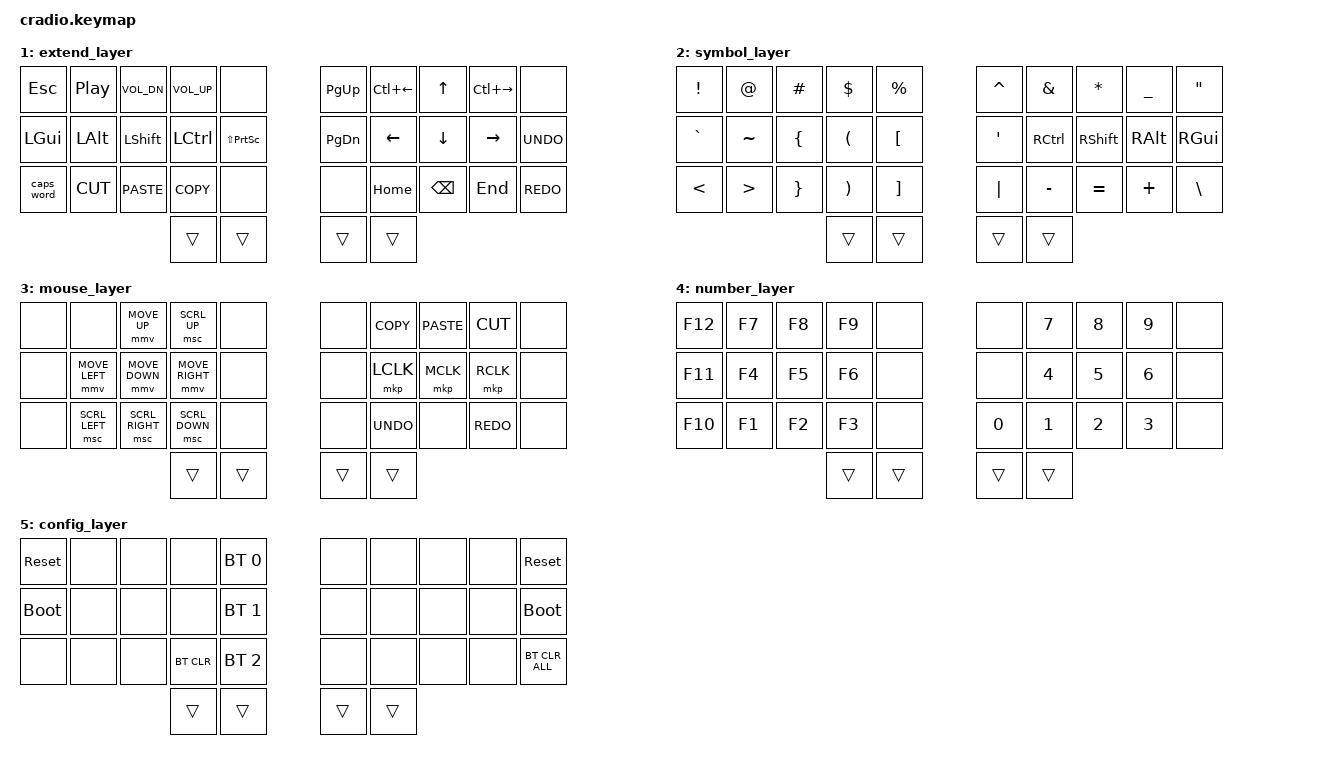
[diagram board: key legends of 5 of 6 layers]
// Copyright (c) 2022 The ZMK Contributors
// SPDX-License-Identifier: MIT

#include <behaviors.dtsi>
#include <dt-bindings/zmk/keys.h>
#include <dt-bindings/zmk/bt.h>
#include <dt-bindings/zmk/mouse.h>

// Home row mods macro
#define HRML(k1,k2,k3,k4) &ht_l LGUI k1  &ht_l LALT k2  &ht LSHFT k3  &ht LCTRL k4
#define HRMR(k1,k2,k3,k4) &ht RCTRL k1  &ht RSHFT k2  &ht_l RALT k3  &ht_l RGUI k4

// Word Nav
#define NXTWD &kp LC(RIGHT)
#define PRVWD &kp LC(LEFT)

// Media
#define VOL_DN &kp C_VOL_DN
#define VOL_UP &kp C_VOL_UP

// Mouse
#define MV_UP &mmv MOVE_UP
#define MV_DOWN &mmv MOVE_DOWN
#define MV_LEFT &mmv MOVE_LEFT
#define MV_RIGHT &mmv MOVE_RIGHT

// Scroll
#define SC_UP &msc SCRL_UP
#define SC_DOWN &msc SCRL_DOWN
#define SC_LEFT &msc SCRL_LEFT
#define SC_RIGHT &msc SCRL_RIGHT

// Screenshot
#define SCN_SHOT &kp LS(PSCRN)

/ {
    behaviors {
        ht: hold_tap {
            compatible = "zmk,behavior-hold-tap";
            #binding-cells = <2>;
            flavor = "tap-preferred";
            tapping-term-ms = <220>;
    		quick-tap-ms = <200>;
    		require-prior-idle-ms = <125>;
            bindings = <&kp>, <&kp>;
        };
        ht_l: hold_tap_long {
            compatible = "zmk,behavior-hold-tap";
            #binding-cells = <2>;
            flavor = "tap-preferred";
            tapping-term-ms = <400>;
    		quick-tap-ms = <200>;
    		require-prior-idle-ms = <125>;
            bindings = <&kp>, <&kp>;
        };
    };

    conditional_layers {
        compatible = "zmk,conditional-layers";
        config_layer {
            if-layers = <1 2>;
            then-layer = <5>;
        };
    };

    keymap {
        compatible = "zmk,keymap";
        default_layer {
            bindings = <
        //╭──────────┬──────────┬──────────┬──────────┬──────────╮   ╭──────────┬──────────┬──────────┬──────────┬──────────╮
        //│  Q       │  W       │  F       │  P       │  B       │   │  J       │  L       │  U       │  Y       │  ; :     │
            &kp Q      &kp W      &kp F      &kp P      &kp B          &kp J      &kp L      &kp U      &kp Y      &kp SEMI
        //├──────────┼──────────┼──────────┼──────────┼──────────┤   ├──────────┼──────────┼──────────┼──────────┼──────────┤
        //│  A       │  R       │  S       │  T       │  G       │   │  M       │  N       │  E       │  I       │  O       │
            HRML(A,    R,         S,         T)         &kp G          &kp M      HRMR(N,    E,         I,         O)
        //├──────────┼──────────┼──────────┼──────────┼──────────┤   ├──────────┼──────────┼──────────┼──────────┼──────────┤
        //│  Z       │  X       │  C       │  D       │  V       │   │  K       │  H       │  , <     │  . >     │  / ?     │
            &kp Z      &kp X      &kp C      &kp D      &kp V          &kp K      &kp H      &kp COMMA  &kp DOT    &kp FSLH
        //╰──────────┴──────────┴──────────┼──────────┼──────────┤   ├──────────┼──────────┼──────────┴──────────┴──────────╯
                                            &lt 2 TAB  &lt 4 SPACE    &lt 3 ENTER &lt 1 BSPC
        //                                 ╰──────────┴──────────╯   ╰──────────┴──────────╯
            >;
        };

        extend_layer {
            bindings = <
        //╭──────────┬──────────┬──────────┬──────────┬──────────╮   ╭──────────┬──────────┬──────────┬──────────┬──────────╮
        //│  ESC     │Play/Pause│  VOL_DN  │  VOL_UP  │          │   │  PG_UP   │  PRVWD   │  UP      │  NXTWD   │          │
            &kp ESC    &kp C_PP   VOL_DN     VOL_UP     &none          &kp PG_UP  PRVWD      &kp UP     NXTWD      &none
        //├──────────┼──────────┼──────────┼──────────┼──────────┤   ├──────────┼──────────┼──────────┼──────────┼──────────┤
        //│  LGUI    │  LALT    │  LSHFT   │  LCTRL   │          │   │  PG_DN   │  LEFT    │  DOWN    │  RIGHT   │  undo    │
            &kp LGUI   &kp LALT   &kp LSHFT  &kp LCTRL  SCN_SHOT       &kp PG_DN  &kp LEFT   &kp DOWN   &kp RIGHT &kp K_UNDO
        //├──────────┼──────────┼──────────┼──────────┼──────────┤   ├──────────┼──────────┼──────────┼──────────┼──────────┤
        //│ CAPS     │  cut     │  paste   │  copy    │          │   │          │  HOME    │  BSPC    │  END     │  redo    │
           &caps_word &kp K_CUT  &kp K_PASTE &kp K_COPY &none          &none      &kp HOME   &kp BSPC   &kp END   &kp K_REDO
        //╰──────────┴──────────┴──────────┼──────────┼──────────┤   ├──────────┼──────────┼──────────┴──────────┴──────────╯
                                             &trans     &trans         &trans     &trans
        //                                 ╰──────────┴──────────╯   ╰──────────┴──────────╯
            >;
        };

        symbol_layer {
            bindings = <
        //╭──────────┬──────────┬──────────┬──────────┬──────────╮   ╭──────────┬──────────┬──────────┬──────────┬──────────╮
        //│  !       │  @       │  #       │  $       │  %       │   │  ^       │  &       │  *       │  _       │  "       │
            &kp EXCL  &kp AT      &kp HASH   &kp DLLR   &kp PRCNT      &kp CARET  &kp AMPS   &kp ASTRK  &kp UNDER  &kp DQT
        //├──────────┼──────────┼──────────┼──────────┼──────────┤   ├──────────┼──────────┼──────────┼──────────┼──────────┤
        //│  `       │  ~       │  {       │  (       │  [       │   │  '       │  RCRTL   │  RSHFT   │  RALT    │  RGUI    │
            &kp GRAVE  &kp TILDE  &kp LBRC   &kp LPAR   &kp LBKT       &kp APOS   &kp RCTRL  &kp RSHFT  &kp RALT   &kp RGUI
        //├──────────┼──────────┼──────────┼──────────┼──────────┤   ├──────────┼──────────┼──────────┼──────────┼──────────┤
        //│  <       │  >       │  }       │  )       │  ]       │   │  |       │  -       │  =       │  +       │  \       │
            &kp LT     &kp GT     &kp RBRC   &kp RPAR   &kp RBKT       &kp PIPE   &kp MINUS  &kp EQUAL  &kp PLUS   &kp BSLH
        //╰──────────┴──────────┴──────────┼──────────┼──────────┤   ├──────────┼──────────┼──────────┴──────────┴──────────╯
                                             &trans     &trans         &trans     &trans
        //                                 ╰──────────┴──────────╯   ╰──────────┴──────────╯
            >;
        };

        mouse_layer {
            bindings = <
        //╭──────────┬──────────┬──────────┬──────────┬──────────╮   ╭──────────┬──────────┬──────────┬──────────┬──────────╮
        //│          │          │          │          │          │   │          │  copy    │  paste   │  cut     │          │
            &none      &none      MV_UP      SC_UP      &none          &none     &kp K_COPY &kp K_PASTE &kp K_CUT  &none
        //├──────────┼──────────┼──────────┼──────────┼──────────┤   ├──────────┼──────────┼──────────┼──────────┼──────────┤
        //│          │          │          │          │          │   │          │  L clk   │  M clk   │  R clk   │          │
            &none      MV_LEFT    MV_DOWN    MV_RIGHT   &none          &none      &mkp LCLK  &mkp MCLK  &mkp RCLK  &none
        //├──────────┼──────────┼──────────┼──────────┼──────────┤   ├──────────┼──────────┼──────────┼──────────┼──────────┤
        //│          │          │          │          │          │   │          │  undo    │          │  redo    │          │
            &none      SC_LEFT   SC_RIGHT    SC_DOWN    &none          &none     &kp K_UNDO  &none     &kp K_REDO  &none
        //╰──────────┴──────────┴──────────┼──────────┼──────────┤   ├──────────┼──────────┼──────────┴──────────┴──────────╯
                                             &trans     &trans         &trans     &trans
        //                                 ╰──────────┴──────────╯   ╰──────────┴──────────╯
            >;
        };

        number_layer {
            bindings = <
        //╭──────────┬──────────┬──────────┬──────────┬──────────╮   ╭──────────┬──────────┬──────────┬──────────┬──────────╮
        //│  F12     │  F7      │  F8      │  F9      │          │   │          │  7       │  8       │  9       │          │
            &kp F12    &kp F7     &kp F8     &kp F9     &none          &none      &kp N7     &kp N8     &kp N9     &none
        //├──────────┼──────────┼──────────┼──────────┼──────────┤   ├──────────┼──────────┼──────────┼──────────┼──────────┤
        //│  F11     │  F4      │  F5      │  F6      │          │   │          │  4       │  5       │  6       │          │
            &kp F11    &kp F4     &kp F5     &kp F6     &none          &none      &kp N4     &kp N5     &kp N6     &none
        //├──────────┼──────────┼──────────┼──────────┼──────────┤   ├──────────┼──────────┼──────────┼──────────┼──────────┤
        //│  F10     │  F1      │  F2      │  F3      │          │   │  0       │  1       │  2       │  3       │          │
            &kp F10    &kp F1     &kp F2     &kp F3     &none          &kp N0     &kp N1     &kp N2     &kp N3     &none
        //╰──────────┴──────────┴──────────┼──────────┼──────────┤   ├──────────┼──────────┼──────────┴──────────┴──────────╯
                                             &trans     &trans         &trans     &trans
        //                                 ╰──────────┴──────────╯   ╰──────────┴──────────╯
            >;
        };

        config_layer {
            bindings = <
        //╭──────────┬──────────┬──────────┬──────────┬──────────╮   ╭──────────┬──────────┬──────────┬──────────┬──────────╮
        //│ RESET    │          │          │          │PROFILE 0 │   │          │          │          │          │  RESET   │
           &sys_reset  &none      &none      &none     &bt BT_SEL 0    &none      &none      &none      &none     &sys_reset
        //├──────────┼──────────┼──────────┼──────────┼──────────┤   ├──────────┼──────────┼──────────┼──────────┼──────────┤
        //│BOOTLOADER│          │          │          │PROFILE 1 │   │          │          │          │          │BOOTLOADER│
          &bootloader  &none      &none      &none     &bt BT_SEL 1    &none      &none      &none      &none     &bootloader
        //├──────────┼──────────┼──────────┼──────────┼──────────┤   ├──────────┼──────────┼──────────┼──────────┼──────────┤
        //│          │          │          │ CLEAR BT │PROFILE 2 │   │          │          │          │          │BT CLR ALL│
            &none      &none      &none     &bt BT_CLR &bt BT_SEL 2    &none      &none      &none      &none     &bt BT_CLR_ALL
        //╰──────────┴──────────┴──────────┼──────────┼──────────┤   ├──────────┼──────────┼──────────┴──────────┴──────────╯
                                             &trans     &trans         &trans     &trans
        //                                 ╰──────────┴──────────╯   ╰──────────┴──────────╯
            >;
        };
    };
};
